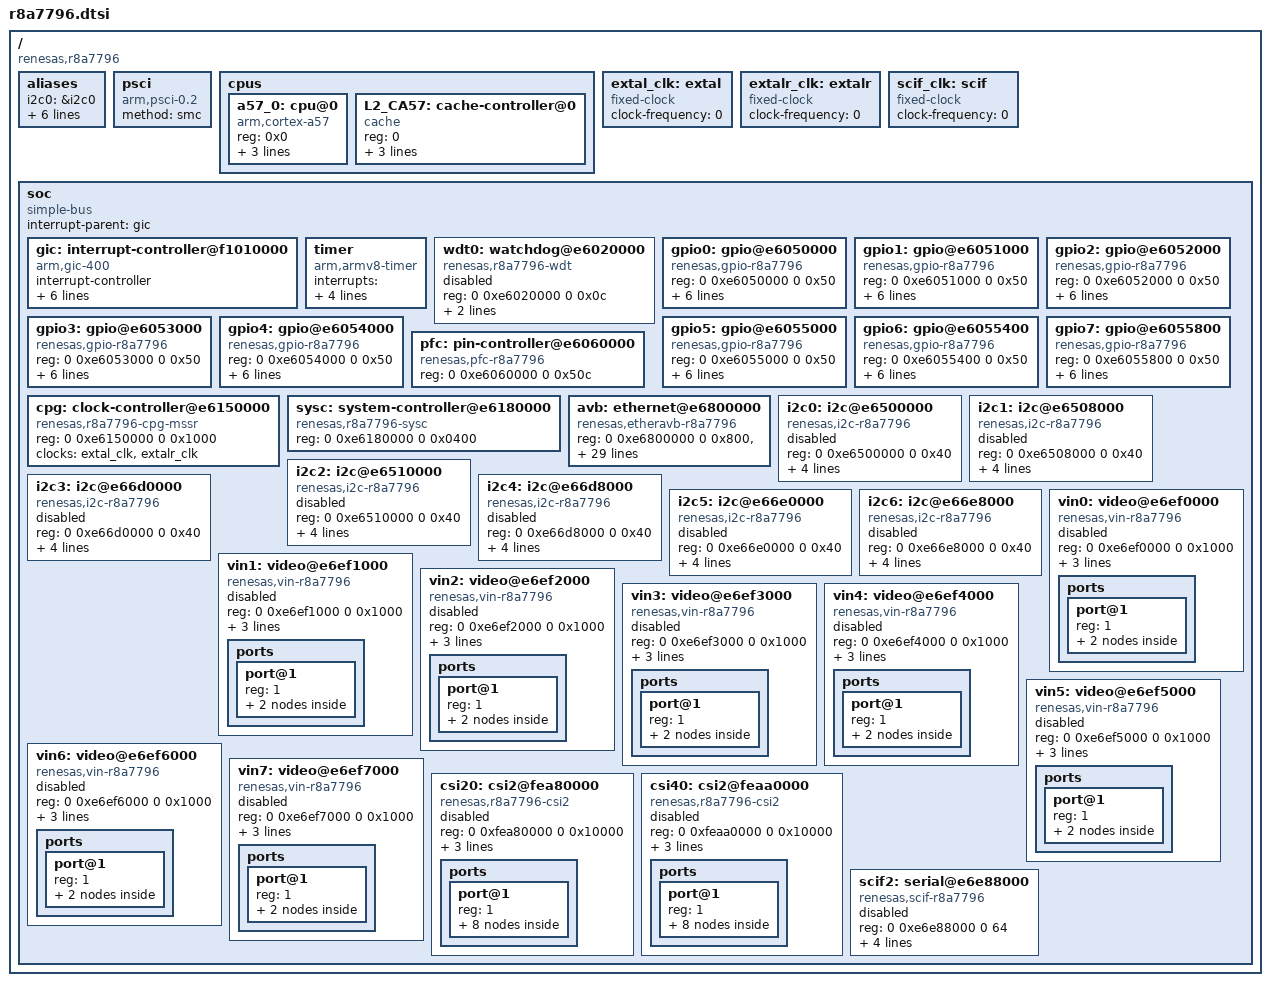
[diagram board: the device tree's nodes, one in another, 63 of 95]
/*
 * Device Tree Source for the r8a7796 SoC
 *
 * Copyright (C) 2016 Renesas Electronics Corp.
 *
 * This file is licensed under the terms of the GNU General Public License
 * version 2.  This program is licensed "as is" without any warranty of any
 * kind, whether express or implied.
 */

#include <dt-bindings/clock/r8a7796-cpg-mssr.h>
#include <dt-bindings/interrupt-controller/arm-gic.h>
#include <dt-bindings/power/r8a7796-sysc.h>

/ {
	compatible = "renesas,r8a7796";
	#address-cells = <2>;
	#size-cells = <2>;

	aliases {
		i2c0 = &i2c0;
		i2c1 = &i2c1;
		i2c2 = &i2c2;
		i2c3 = &i2c3;
		i2c4 = &i2c4;
		i2c5 = &i2c5;
		i2c6 = &i2c6;
	};

	psci {
		compatible = "arm,psci-0.2";
		method = "smc";
	};

	cpus {
		#address-cells = <1>;
		#size-cells = <0>;

		/* 1 core only at this point */
		a57_0: cpu@0 {
			compatible = "arm,cortex-a57", "arm,armv8";
			reg = <0x0>;
			device_type = "cpu";
			power-domains = <&sysc R8A7796_PD_CA57_CPU0>;
			next-level-cache = <&L2_CA57>;
			enable-method = "psci";
		};

		L2_CA57: cache-controller@0 {
			compatible = "cache";
			reg = <0>;
			power-domains = <&sysc R8A7796_PD_CA57_SCU>;
			cache-unified;
			cache-level = <2>;
		};
	};

	extal_clk: extal {
		compatible = "fixed-clock";
		#clock-cells = <0>;
		/* This value must be overridden by the board */
		clock-frequency = <0>;
	};

	extalr_clk: extalr {
		compatible = "fixed-clock";
		#clock-cells = <0>;
		/* This value must be overridden by the board */
		clock-frequency = <0>;
	};

	/* External SCIF clock - to be overridden by boards that provide it */
	scif_clk: scif {
		compatible = "fixed-clock";
		#clock-cells = <0>;
		clock-frequency = <0>;
	};

	soc {
		compatible = "simple-bus";
		interrupt-parent = <&gic>;
		#address-cells = <2>;
		#size-cells = <2>;
		ranges;

		gic: interrupt-controller@f1010000 {
			compatible = "arm,gic-400";
			#interrupt-cells = <3>;
			#address-cells = <0>;
			interrupt-controller;
			reg = <0x0 0xf1010000 0 0x1000>,
			      <0x0 0xf1020000 0 0x20000>,
			      <0x0 0xf1040000 0 0x20000>,
			      <0x0 0xf1060000 0 0x20000>;
			interrupts = <GIC_PPI 9
					(GIC_CPU_MASK_SIMPLE(1) | IRQ_TYPE_LEVEL_HIGH)>;
		};

		timer {
			compatible = "arm,armv8-timer";
			interrupts = <GIC_PPI 13
					(GIC_CPU_MASK_SIMPLE(1) | IRQ_TYPE_LEVEL_LOW)>,
				     <GIC_PPI 14
					(GIC_CPU_MASK_SIMPLE(1) | IRQ_TYPE_LEVEL_LOW)>,
				     <GIC_PPI 11
					(GIC_CPU_MASK_SIMPLE(1) | IRQ_TYPE_LEVEL_LOW)>,
				     <GIC_PPI 10
					(GIC_CPU_MASK_SIMPLE(1) | IRQ_TYPE_LEVEL_LOW)>;
		};

		wdt0: watchdog@e6020000 {
			compatible = "renesas,r8a7796-wdt",
				     "renesas,rcar-gen3-wdt";
			reg = <0 0xe6020000 0 0x0c>;
			clocks = <&cpg CPG_MOD 402>;
			power-domains = <&sysc R8A7796_PD_ALWAYS_ON>;
			status = "disabled";
		};

		gpio0: gpio@e6050000 {
			compatible = "renesas,gpio-r8a7796",
				     "renesas,gpio-rcar";
			reg = <0 0xe6050000 0 0x50>;
			interrupts = <GIC_SPI 4 IRQ_TYPE_LEVEL_HIGH>;
			#gpio-cells = <2>;
			gpio-controller;
			gpio-ranges = <&pfc 0 0 16>;
			#interrupt-cells = <2>;
			interrupt-controller;
			clocks = <&cpg CPG_MOD 912>;
			power-domains = <&sysc R8A7796_PD_ALWAYS_ON>;
		};

		gpio1: gpio@e6051000 {
			compatible = "renesas,gpio-r8a7796",
				     "renesas,gpio-rcar";
			reg = <0 0xe6051000 0 0x50>;
			interrupts = <GIC_SPI 5 IRQ_TYPE_LEVEL_HIGH>;
			#gpio-cells = <2>;
			gpio-controller;
			gpio-ranges = <&pfc 0 32 29>;
			#interrupt-cells = <2>;
			interrupt-controller;
			clocks = <&cpg CPG_MOD 911>;
			power-domains = <&sysc R8A7796_PD_ALWAYS_ON>;
		};

		gpio2: gpio@e6052000 {
			compatible = "renesas,gpio-r8a7796",
				     "renesas,gpio-rcar";
			reg = <0 0xe6052000 0 0x50>;
			interrupts = <GIC_SPI 6 IRQ_TYPE_LEVEL_HIGH>;
			#gpio-cells = <2>;
			gpio-controller;
			gpio-ranges = <&pfc 0 64 15>;
			#interrupt-cells = <2>;
			interrupt-controller;
			clocks = <&cpg CPG_MOD 910>;
			power-domains = <&sysc R8A7796_PD_ALWAYS_ON>;
		};

		gpio3: gpio@e6053000 {
			compatible = "renesas,gpio-r8a7796",
				     "renesas,gpio-rcar";
			reg = <0 0xe6053000 0 0x50>;
			interrupts = <GIC_SPI 7 IRQ_TYPE_LEVEL_HIGH>;
			#gpio-cells = <2>;
			gpio-controller;
			gpio-ranges = <&pfc 0 96 16>;
			#interrupt-cells = <2>;
			interrupt-controller;
			clocks = <&cpg CPG_MOD 909>;
			power-domains = <&sysc R8A7796_PD_ALWAYS_ON>;
		};

		gpio4: gpio@e6054000 {
			compatible = "renesas,gpio-r8a7796",
				     "renesas,gpio-rcar";
			reg = <0 0xe6054000 0 0x50>;
			interrupts = <GIC_SPI 8 IRQ_TYPE_LEVEL_HIGH>;
			#gpio-cells = <2>;
			gpio-controller;
			gpio-ranges = <&pfc 0 128 18>;
			#interrupt-cells = <2>;
			interrupt-controller;
			clocks = <&cpg CPG_MOD 908>;
			power-domains = <&sysc R8A7796_PD_ALWAYS_ON>;
		};

		gpio5: gpio@e6055000 {
			compatible = "renesas,gpio-r8a7796",
				     "renesas,gpio-rcar";
			reg = <0 0xe6055000 0 0x50>;
			interrupts = <GIC_SPI 9 IRQ_TYPE_LEVEL_HIGH>;
			#gpio-cells = <2>;
			gpio-controller;
			gpio-ranges = <&pfc 0 160 26>;
			#interrupt-cells = <2>;
			interrupt-controller;
			clocks = <&cpg CPG_MOD 907>;
			power-domains = <&sysc R8A7796_PD_ALWAYS_ON>;
		};

		gpio6: gpio@e6055400 {
			compatible = "renesas,gpio-r8a7796",
				     "renesas,gpio-rcar";
			reg = <0 0xe6055400 0 0x50>;
			interrupts = <GIC_SPI 10 IRQ_TYPE_LEVEL_HIGH>;
			#gpio-cells = <2>;
			gpio-controller;
			gpio-ranges = <&pfc 0 192 32>;
			#interrupt-cells = <2>;
			interrupt-controller;
			clocks = <&cpg CPG_MOD 906>;
			power-domains = <&sysc R8A7796_PD_ALWAYS_ON>;
		};

		gpio7: gpio@e6055800 {
			compatible = "renesas,gpio-r8a7796",
				     "renesas,gpio-rcar";
			reg = <0 0xe6055800 0 0x50>;
			interrupts = <GIC_SPI 11 IRQ_TYPE_LEVEL_HIGH>;
			#gpio-cells = <2>;
			gpio-controller;
			gpio-ranges = <&pfc 0 224 4>;
			#interrupt-cells = <2>;
			interrupt-controller;
			clocks = <&cpg CPG_MOD 905>;
			power-domains = <&sysc R8A7796_PD_ALWAYS_ON>;
		};

		pfc: pin-controller@e6060000 {
			compatible = "renesas,pfc-r8a7796";
			reg = <0 0xe6060000 0 0x50c>;
		};

		cpg: clock-controller@e6150000 {
			compatible = "renesas,r8a7796-cpg-mssr";
			reg = <0 0xe6150000 0 0x1000>;
			clocks = <&extal_clk>, <&extalr_clk>;
			clock-names = "extal", "extalr";
			#clock-cells = <2>;
			#power-domain-cells = <0>;
		};

		sysc: system-controller@e6180000 {
			compatible = "renesas,r8a7796-sysc";
			reg = <0 0xe6180000 0 0x0400>;
			#power-domain-cells = <1>;
		};

		avb: ethernet@e6800000 {
			compatible = "renesas,etheravb-r8a7796",
				     "renesas,etheravb-rcar-gen3";
			reg = <0 0xe6800000 0 0x800>, <0 0xe6a00000 0 0x10000>;
			interrupts = <GIC_SPI 39 IRQ_TYPE_LEVEL_HIGH>,
				     <GIC_SPI 40 IRQ_TYPE_LEVEL_HIGH>,
				     <GIC_SPI 41 IRQ_TYPE_LEVEL_HIGH>,
				     <GIC_SPI 42 IRQ_TYPE_LEVEL_HIGH>,
				     <GIC_SPI 43 IRQ_TYPE_LEVEL_HIGH>,
				     <GIC_SPI 44 IRQ_TYPE_LEVEL_HIGH>,
				     <GIC_SPI 45 IRQ_TYPE_LEVEL_HIGH>,
				     <GIC_SPI 46 IRQ_TYPE_LEVEL_HIGH>,
				     <GIC_SPI 47 IRQ_TYPE_LEVEL_HIGH>,
				     <GIC_SPI 48 IRQ_TYPE_LEVEL_HIGH>,
				     <GIC_SPI 49 IRQ_TYPE_LEVEL_HIGH>,
				     <GIC_SPI 50 IRQ_TYPE_LEVEL_HIGH>,
				     <GIC_SPI 51 IRQ_TYPE_LEVEL_HIGH>,
				     <GIC_SPI 52 IRQ_TYPE_LEVEL_HIGH>,
				     <GIC_SPI 53 IRQ_TYPE_LEVEL_HIGH>,
				     <GIC_SPI 54 IRQ_TYPE_LEVEL_HIGH>,
				     <GIC_SPI 55 IRQ_TYPE_LEVEL_HIGH>,
				     <GIC_SPI 56 IRQ_TYPE_LEVEL_HIGH>,
				     <GIC_SPI 57 IRQ_TYPE_LEVEL_HIGH>,
				     <GIC_SPI 58 IRQ_TYPE_LEVEL_HIGH>,
				     <GIC_SPI 59 IRQ_TYPE_LEVEL_HIGH>,
				     <GIC_SPI 60 IRQ_TYPE_LEVEL_HIGH>,
				     <GIC_SPI 61 IRQ_TYPE_LEVEL_HIGH>,
				     <GIC_SPI 62 IRQ_TYPE_LEVEL_HIGH>,
				     <GIC_SPI 63 IRQ_TYPE_LEVEL_HIGH>;
			interrupt-names = "ch0", "ch1", "ch2", "ch3",
					  "ch4", "ch5", "ch6", "ch7",
					  "ch8", "ch9", "ch10", "ch11",
					  "ch12", "ch13", "ch14", "ch15",
					  "ch16", "ch17", "ch18", "ch19",
					  "ch20", "ch21", "ch22", "ch23",
					  "ch24";
			clocks = <&cpg CPG_MOD 812>;
			power-domains = <&sysc R8A7796_PD_ALWAYS_ON>;
			phy-mode = "rgmii-id";
			#address-cells = <1>;
			#size-cells = <0>;
		};

		i2c0: i2c@e6500000 {
			#address-cells = <1>;
			#size-cells = <0>;
			compatible = "renesas,i2c-r8a7796";
			reg = <0 0xe6500000 0 0x40>;
			interrupts = <GIC_SPI 287 IRQ_TYPE_LEVEL_HIGH>;
			clocks = <&cpg CPG_MOD 931>;
			power-domains = <&sysc R8A7796_PD_ALWAYS_ON>;
			i2c-scl-internal-delay-ns = <110>;
			status = "disabled";
		};

		i2c1: i2c@e6508000 {
			#address-cells = <1>;
			#size-cells = <0>;
			compatible = "renesas,i2c-r8a7796";
			reg = <0 0xe6508000 0 0x40>;
			interrupts = <GIC_SPI 288 IRQ_TYPE_LEVEL_HIGH>;
			clocks = <&cpg CPG_MOD 930>;
			power-domains = <&sysc R8A7796_PD_ALWAYS_ON>;
			i2c-scl-internal-delay-ns = <6>;
			status = "disabled";
		};

		i2c2: i2c@e6510000 {
			#address-cells = <1>;
			#size-cells = <0>;
			compatible = "renesas,i2c-r8a7796";
			reg = <0 0xe6510000 0 0x40>;
			interrupts = <GIC_SPI 286 IRQ_TYPE_LEVEL_HIGH>;
			clocks = <&cpg CPG_MOD 929>;
			power-domains = <&sysc R8A7796_PD_ALWAYS_ON>;
			i2c-scl-internal-delay-ns = <6>;
			status = "disabled";
		};

		i2c3: i2c@e66d0000 {
			#address-cells = <1>;
			#size-cells = <0>;
			compatible = "renesas,i2c-r8a7796";
			reg = <0 0xe66d0000 0 0x40>;
			interrupts = <GIC_SPI 290 IRQ_TYPE_LEVEL_HIGH>;
			clocks = <&cpg CPG_MOD 928>;
			power-domains = <&sysc R8A7796_PD_ALWAYS_ON>;
			i2c-scl-internal-delay-ns = <110>;
			status = "disabled";
		};

		i2c4: i2c@e66d8000 {
			#address-cells = <1>;
			#size-cells = <0>;
			compatible = "renesas,i2c-r8a7796";
			reg = <0 0xe66d8000 0 0x40>;
			interrupts = <GIC_SPI 19 IRQ_TYPE_LEVEL_HIGH>;
			clocks = <&cpg CPG_MOD 927>;
			power-domains = <&sysc R8A7796_PD_ALWAYS_ON>;
			i2c-scl-internal-delay-ns = <110>;
			status = "disabled";
		};

		i2c5: i2c@e66e0000 {
			#address-cells = <1>;
			#size-cells = <0>;
			compatible = "renesas,i2c-r8a7796";
			reg = <0 0xe66e0000 0 0x40>;
			interrupts = <GIC_SPI 20 IRQ_TYPE_LEVEL_HIGH>;
			clocks = <&cpg CPG_MOD 919>;
			power-domains = <&sysc R8A7796_PD_ALWAYS_ON>;
			i2c-scl-internal-delay-ns = <110>;
			status = "disabled";
		};

		i2c6: i2c@e66e8000 {
			#address-cells = <1>;
			#size-cells = <0>;
			compatible = "renesas,i2c-r8a7796";
			reg = <0 0xe66e8000 0 0x40>;
			interrupts = <GIC_SPI 21 IRQ_TYPE_LEVEL_HIGH>;
			clocks = <&cpg CPG_MOD 918>;
			power-domains = <&sysc R8A7796_PD_ALWAYS_ON>;
			i2c-scl-internal-delay-ns = <6>;
			status = "disabled";
		};

		vin0: video@e6ef0000 {
			compatible = "renesas,vin-r8a7796";
			reg = <0 0xe6ef0000 0 0x1000>;
			interrupts = <0 188 IRQ_TYPE_LEVEL_HIGH>;
			clocks = <&cpg CPG_MOD 811>;
			power-domains = <&cpg>;
			status = "disabled";

			ports {
				#address-cells = <1>;
				#size-cells = <0>;

				port@1 {
					#address-cells = <1>;
					#size-cells = <0>;

					reg = <1>;

					vin0csi20: endpoint@0 {
						reg = <0>;
						remote-endpoint= <&csi20vin0>;
					};
					vin0csi40: endpoint@2 {
						reg = <2>;
						remote-endpoint= <&csi40vin0>;
					};
				};
			};
		};

		vin1: video@e6ef1000 {
			compatible = "renesas,vin-r8a7796";
			reg =  <0 0xe6ef1000 0 0x1000>;
			interrupts = <0 189 IRQ_TYPE_LEVEL_HIGH>;
			clocks = <&cpg CPG_MOD 810>;
			power-domains = <&cpg>;
			status = "disabled";

			ports {
				#address-cells = <1>;
				#size-cells = <0>;

				port@1 {
					#address-cells = <1>;
					#size-cells = <0>;

					reg = <1>;

					vin1csi20: endpoint@0 {
						reg = <0>;
						remote-endpoint= <&csi20vin1>;
					};
					vin1csi40: endpoint@2 {
						reg = <2>;
						remote-endpoint= <&csi40vin1>;
					};
				};
			};
		};

		vin2: video@e6ef2000 {
			compatible = "renesas,vin-r8a7796";
			reg = <0 0xe6ef2000 0 0x1000>;
			interrupts = <0 190 IRQ_TYPE_LEVEL_HIGH>;
			clocks = <&cpg CPG_MOD 809>;
			power-domains = <&cpg>;
			status = "disabled";

			ports {
				#address-cells = <1>;
				#size-cells = <0>;

				port@1 {
					#address-cells = <1>;
					#size-cells = <0>;

					reg = <1>;

					vin2csi20: endpoint@0 {
						reg = <0>;
						remote-endpoint= <&csi20vin2>;
					};
					vin2csi40: endpoint@2 {
						reg = <2>;
						remote-endpoint= <&csi40vin2>;
					};
				};
			};
		};

		vin3: video@e6ef3000 {
			compatible = "renesas,vin-r8a7796";
			reg = <0 0xe6ef3000 0 0x1000>;
			interrupts = <0 191 IRQ_TYPE_LEVEL_HIGH>;
			clocks = <&cpg CPG_MOD 808>;
			power-domains = <&cpg>;
			status = "disabled";

			ports {
				#address-cells = <1>;
				#size-cells = <0>;

				port@1 {
					#address-cells = <1>;
					#size-cells = <0>;

					reg = <1>;

					vin3csi20: endpoint@0 {
						reg = <0>;
						remote-endpoint= <&csi20vin3>;
					};
					vin3csi40: endpoint@2 {
						reg = <2>;
						remote-endpoint= <&csi40vin3>;
					};
				};
			};
		};

		vin4: video@e6ef4000 {
			compatible = "renesas,vin-r8a7796";
			reg = <0 0xe6ef4000 0 0x1000>;
			interrupts = <0 174 IRQ_TYPE_LEVEL_HIGH>;
			clocks = <&cpg CPG_MOD 807>;
			power-domains = <&cpg>;
			status = "disabled";

			ports {
				#address-cells = <1>;
				#size-cells = <0>;

				port@1 {
					#address-cells = <1>;
					#size-cells = <0>;

					reg = <1>;

					vin4csi20: endpoint@0 {
						reg = <0>;
						remote-endpoint= <&csi20vin4>;
					};
					vin4csi40: endpoint@2 {
						reg = <2>;
						remote-endpoint= <&csi40vin4>;
					};
				};
			};
		};

		vin5: video@e6ef5000 {
			compatible = "renesas,vin-r8a7796";
			reg = <0 0xe6ef5000 0 0x1000>;
			interrupts = <0 175 IRQ_TYPE_LEVEL_HIGH>;
			clocks = <&cpg CPG_MOD 806>;
			power-domains = <&cpg>;
			status = "disabled";

			ports {
				#address-cells = <1>;
				#size-cells = <0>;

				port@1 {
					#address-cells = <1>;
					#size-cells = <0>;

					reg = <1>;

					vin5csi20: endpoint@0 {
						reg = <0>;
						remote-endpoint= <&csi20vin5>;
					};
					vin5csi40: endpoint@2 {
						reg = <2>;
						remote-endpoint= <&csi40vin5>;
					};
				};
			};
		};

		vin6: video@e6ef6000 {
			compatible = "renesas,vin-r8a7796";
			reg = <0 0xe6ef6000 0 0x1000>;
			interrupts = <0 176 IRQ_TYPE_LEVEL_HIGH>;
			clocks = <&cpg CPG_MOD 805>;
			power-domains = <&cpg>;
			status = "disabled";

			ports {
				#address-cells = <1>;
				#size-cells = <0>;

				port@1 {
					#address-cells = <1>;
					#size-cells = <0>;

					reg = <1>;

					vin6csi20: endpoint@0 {
						reg = <0>;
						remote-endpoint= <&csi20vin6>;
					};
					vin6csi40: endpoint@2 {
						reg = <2>;
						remote-endpoint= <&csi40vin6>;
					};
				};
			};
		};

		vin7: video@e6ef7000 {
			compatible = "renesas,vin-r8a7796";
			reg = <0 0xe6ef7000 0 0x1000>;
			interrupts = <0 171 IRQ_TYPE_LEVEL_HIGH>;
			clocks = <&cpg CPG_MOD 804>;
			power-domains = <&cpg>;
			status = "disabled";

			ports {
				#address-cells = <1>;
				#size-cells = <0>;

				port@1 {
					#address-cells = <1>;
					#size-cells = <0>;

					reg = <1>;

					vin7csi20: endpoint@0 {
						reg = <0>;
						remote-endpoint= <&csi20vin7>;
					};
					vin7csi40: endpoint@2 {
						reg = <2>;
						remote-endpoint= <&csi40vin7>;
					};
				};
			};
		};

		csi20: csi2@fea80000 {
			compatible = "renesas,r8a7796-csi2";
			reg = <0 0xfea80000 0 0x10000>;
			interrupts = <0 184 IRQ_TYPE_LEVEL_HIGH>;
			clocks = <&cpg CPG_MOD 714>;
			power-domains = <&cpg>;
			status = "disabled";

			ports {
				#address-cells = <1>;
				#size-cells = <0>;

				port@1 {
					#address-cells = <1>;
					#size-cells = <0>;

					reg = <1>;

					csi20vin0: endpoint@0 {
						reg = <0>;
						remote-endpoint = <&vin0csi20>;
					};
					csi20vin1: endpoint@1 {
						reg = <1>;
						remote-endpoint = <&vin1csi20>;
					};
					csi20vin2: endpoint@2 {
						reg = <2>;
						remote-endpoint = <&vin2csi20>;
					};
					csi20vin3: endpoint@3 {
						reg = <3>;
						remote-endpoint = <&vin3csi20>;
					};
					csi20vin4: endpoint@4 {
						reg = <4>;
						remote-endpoint = <&vin4csi20>;
					};
					csi20vin5: endpoint@5 {
						reg = <5>;
						remote-endpoint = <&vin5csi20>;
					};
					csi20vin6: endpoint@6 {
						reg = <6>;
						remote-endpoint = <&vin6csi20>;
					};
					csi20vin7: endpoint@7 {
						reg = <7>;
						remote-endpoint = <&vin7csi20>;
					};
				};
			};
		};

		csi40: csi2@feaa0000 {
			compatible = "renesas,r8a7796-csi2";
			reg = <0 0xfeaa0000 0 0x10000>;
			interrupts = <0 246 IRQ_TYPE_LEVEL_HIGH>;
			clocks = <&cpg CPG_MOD 716>;
			power-domains = <&cpg>;
			status = "disabled";

			ports {
				#address-cells = <1>;
				#size-cells = <0>;

				port@1 {
					#address-cells = <1>;
					#size-cells = <0>;

					reg = <1>;

					csi40vin0: endpoint@0 {
						reg = <0>;
						remote-endpoint = <&vin0csi40>;
					};
					csi40vin1: endpoint@1 {
						reg = <1>;
						remote-endpoint = <&vin1csi40>;
					};
					csi40vin2: endpoint@2 {
						reg = <2>;
						remote-endpoint = <&vin2csi40>;
					};
					csi40vin3: endpoint@3 {
						reg = <3>;
						remote-endpoint = <&vin3csi40>;
					};
					csi40vin4: endpoint@4 {
						reg = <4>;
						remote-endpoint = <&vin4csi40>;
					};
					csi40vin5: endpoint@5 {
						reg = <5>;
						remote-endpoint = <&vin5csi40>;
					};
					csi40vin6: endpoint@6 {
						reg = <6>;
						remote-endpoint = <&vin6csi40>;
					};
					csi40vin7: endpoint@7 {
						reg = <7>;
						remote-endpoint = <&vin7csi40>;
					};
				};

			};
		};

		scif2: serial@e6e88000 {
			compatible = "renesas,scif-r8a7796",
				     "renesas,rcar-gen3-scif", "renesas,scif";
			reg = <0 0xe6e88000 0 64>;
			interrupts = <GIC_SPI 164 IRQ_TYPE_LEVEL_HIGH>;
			clocks = <&cpg CPG_MOD 310>,
				 <&cpg CPG_CORE R8A7796_CLK_S3D1>,
				 <&scif_clk>;
			clock-names = "fck", "brg_int", "scif_clk";
			power-domains = <&sysc R8A7796_PD_ALWAYS_ON>;
			status = "disabled";
		};
	};
};
